AUTOSAR XML (schema 4-3-0)
package /CollisionDetectionApplicationLayer/ApplicationPackage
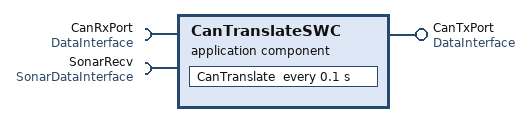
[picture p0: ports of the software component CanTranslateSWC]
  application sw component type CanTranslateSWC
    require port CanRxPort: required-interface=DataInterface
    provide port CanTxPort: provided-interface=DataInterface
    require port SonarRecv: required-interface=SonarDataInterface
    behavior CanTranslateSWCBehaviour: data-type-mapping=TypeMappings, handle-termination-and-restart=NO-SUPPORT
      timing event CanTranslate_timingEvent_0_1: start-on-event=CanTranslate, period=0.1
      runnable CanTranslate: symbol=canTranslate
        data-read-access:
          access dataReadAccess_CanTranslate_SonarRecv_distance: accessed-variable=SonarRecv.distance
          access dataReadAccess_CanTranslate_CanRxPort_message: accessed-variable=CanRxPort.message
        data-write-access:
          access dataWriteAccess_CanTranslate_CanTxPort_message: accessed-variable=CanTxPort.message
  swc implementation CanTranslateSWCImpl: programming-language=C, vendor-id=0, behavior=CanTranslateSWCBehaviour
    code-descriptors:
      code src: artifact-descriptors=autosar-engineering-object={short-label=artifactDescriptor, category=artifactDescriptorCategory}
    resource consumption resourceConsumption
